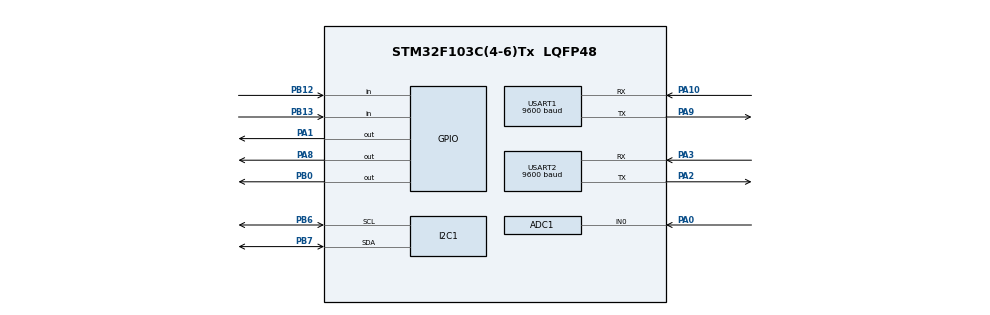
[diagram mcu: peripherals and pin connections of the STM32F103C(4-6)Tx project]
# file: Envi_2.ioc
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ADC1.Channel-7\#ChannelRegularConversion=ADC_CHANNEL_0
ADC1.NbrOfConversionFlag=1
ADC1.Rank-7\#ChannelRegularConversion=1
ADC1.SamplingTime-7\#ChannelRegularConversion=ADC_SAMPLETIME_1CYCLE_5
ADC1.master=1
Mcu.Family=STM32F1
Mcu.Name=STM32F103C(4-6)Tx
Mcu.Package=LQFP48
NVIC.PriorityGroup=NVIC_PRIORITYGROUP_4
PA0-WKUP.Signal=ADCx_IN0
PA1.Signal=GPIO_Output
PA10.Mode=Asynchronous
PA10.Signal=USART1_RX
PA13.Mode=Serial_Wire
PA13.Signal=SYS_JTMS-SWDIO
PA14.Mode=Serial_Wire
PA14.Signal=SYS_JTCK-SWCLK
PA2.Mode=Asynchronous
PA2.Signal=USART2_TX
PA3.Mode=Asynchronous
PA3.Signal=USART2_RX
PA8.Signal=GPIO_Output
PA9.Mode=Asynchronous
PA9.Signal=USART1_TX
PB0.Signal=GPIO_Output
PB12.Signal=GPIO_Input
PB13.Signal=GPIO_Input
PB6.Mode=I2C
PB6.Signal=I2C1_SCL
PB7.Mode=I2C
PB7.Signal=I2C1_SDA
ProjectManager.HeapSize=0x200
ProjectManager.StackSize=0x400
ProjectManager.TargetToolchain=STM32CubeIDE
RCC.APB1Freq_Value=8000000
RCC.APB2Freq_Value=8000000
RCC.SYSCLKSource=RCC_SYSCLKSOURCE_PLLCLK
SH.ADCx_IN0.0=ADC2_IN0
SH.ADCx_IN0.1=ADC1_IN0,IN0
TIM2.Prescaler=7
USART1.BaudRate=9600
USART1.VirtualMode=VM_ASYNC
USART2.BaudRate=9600
USART2.VirtualMode=VM_ASYNC
VP_TIM2_VS_ClockSourceINT.Mode=Internal
board=custom

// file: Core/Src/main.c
/* USER CODE BEGIN Header */
/**
  ******************************************************************************
  * @file           : main.c
  * @brief          : Main program body
  ******************************************************************************
  * @attention
  *
  * Copyright (c) 2026 STMicroelectronics.
  * All rights reserved.
  *
  * This software is licensed under terms that can be found in the LICENSE file
  * in the root directory of this software component.
  * If no LICENSE file comes with this software, it is provided AS-IS.
  *
  ******************************************************************************
  */
/* USER CODE END Header */
#include "main.h"
#include "adc.h"
#include "i2c.h"
#include "tim.h"
#include "usart.h"
#include "gpio.h"

/* USER CODE BEGIN Includes */
#include <stdio.h>
#include <string.h>
#include "bsp_led.h"
#include "bsp_buzzer.h"
#include "bsp_uart.h"
#include "bsp_gas.h"
#include "bsp_button.h"
#include "app.h"
/* USER CODE END Includes */

/* USER CODE BEGIN PV */
uint32_t gas_adc = 0;
uint8_t alarm_mute = 0;
uint8_t gas_alert = 0;
uint32_t gas_threshold = 2000;
/* USER CODE END PV */

void SystemClock_Config(void);

int main(void)
{

  /* MCU Configuration--------------------------------------------------------*/

  /* Reset of all peripherals, Initializes the Flash interface and the Systick. */
  HAL_Init();

  /* Configure the system clock */
  SystemClock_Config();

  /* Initialize all configured peripherals */
  MX_GPIO_Init();
  MX_ADC1_Init();
  MX_USART1_UART_Init();
  MX_USART2_UART_Init();
  MX_I2C1_Init();
  MX_TIM2_Init();
  /* USER CODE BEGIN 2 */
  APP_Init();
  /* USER CODE END 2 */

  /* Infinite loop */
  /* USER CODE BEGIN WHILE */
  while (1)
  {
	  APP_Run();
    /* USER CODE END WHILE */

  }
}

void SystemClock_Config(void)
{
  RCC_OscInitTypeDef RCC_OscInitStruct = {0};
  RCC_ClkInitTypeDef RCC_ClkInitStruct = {0};
  RCC_PeriphCLKInitTypeDef PeriphClkInit = {0};

  /** Initializes the RCC Oscillators according to the specified parameters
  * in the RCC_OscInitTypeDef structure.
  */
  RCC_OscInitStruct.OscillatorType = RCC_OSCILLATORTYPE_HSI;
  RCC_OscInitStruct.HSIState = RCC_HSI_ON;
  RCC_OscInitStruct.HSICalibrationValue = RCC_HSICALIBRATION_DEFAULT;
  RCC_OscInitStruct.PLL.PLLState = RCC_PLL_ON;
  RCC_OscInitStruct.PLL.PLLSource = RCC_PLLSOURCE_HSI_DIV2;
  RCC_OscInitStruct.PLL.PLLMUL = RCC_PLL_MUL2;
  if (HAL_RCC_OscConfig(&RCC_OscInitStruct) != HAL_OK)
  {
    Error_Handler();
  }

  /** Initializes the CPU, AHB and APB buses clocks
  */
  RCC_ClkInitStruct.ClockType = RCC_CLOCKTYPE_HCLK|RCC_CLOCKTYPE_SYSCLK
                              |RCC_CLOCKTYPE_PCLK1|RCC_CLOCKTYPE_PCLK2;
  RCC_ClkInitStruct.SYSCLKSource = RCC_SYSCLKSOURCE_PLLCLK;
  RCC_ClkInitStruct.AHBCLKDivider = RCC_SYSCLK_DIV1;
  RCC_ClkInitStruct.APB1CLKDivider = RCC_HCLK_DIV1;
  RCC_ClkInitStruct.APB2CLKDivider = RCC_HCLK_DIV1;

  if (HAL_RCC_ClockConfig(&RCC_ClkInitStruct, FLASH_LATENCY_0) != HAL_OK)
  {
    Error_Handler();
  }
  PeriphClkInit.PeriphClockSelection = RCC_PERIPHCLK_ADC;
  PeriphClkInit.AdcClockSelection = RCC_ADCPCLK2_DIV2;
  if (HAL_RCCEx_PeriphCLKConfig(&PeriphClkInit) != HAL_OK)
  {
    Error_Handler();
  }
}

void Error_Handler(void)
{
  __disable_irq();
  while (1)
  {
  }
}
